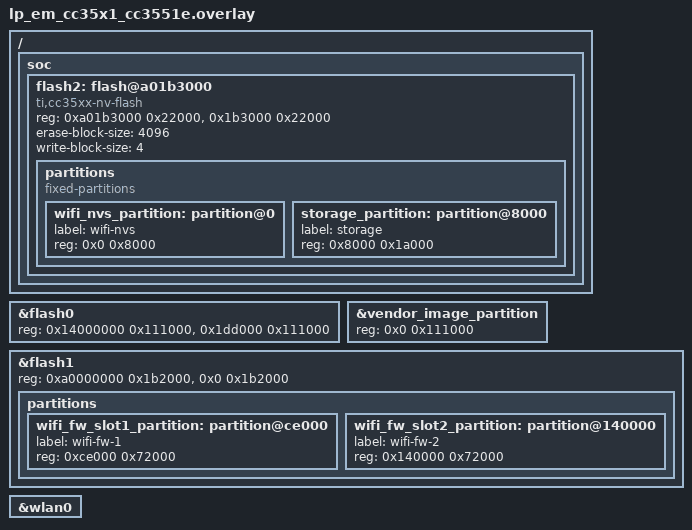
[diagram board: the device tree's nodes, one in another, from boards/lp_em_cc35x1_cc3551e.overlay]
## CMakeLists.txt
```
cmake_minimum_required(VERSION 3.20.0)

if(EXISTS "${CMAKE_CURRENT_SOURCE_DIR}/credentials.conf")
    list(APPEND EXTRA_CONF_FILE "${CMAKE_CURRENT_SOURCE_DIR}/credentials.conf")
endif()

find_package(Zephyr REQUIRED HINTS $ENV{ZEPHYR_BASE})
project(ota_psa)

if(NOT CONFIG_BOARD_LP_EM_CC35X1_CC3551E OR
    NOT CONFIG_CC35XXE_FLASH_PROFILE_IS25WJ032F OR
    NOT CONFIG_CC35XXE_GENERATE_FLASH_MAP_CONFIG)
    message(FATAL_ERROR
        "This sample requires lp_em_cc35x1/cc3551e and the generated is25wj032f OTA map")
endif()

# The overlay fixes physical addresses. A profile name alone cannot validate a
# custom map or discovery configuration against those addresses.
if(NOT "${CONFIG_CC35XXE_MEMORY_CONFIG_JSON}" STREQUAL "" OR
    NOT "${CONFIG_CC35XXE_FLASH_DISCOVERY_CONFIG_EXT_MEM}" STREQUAL "" OR
    NOT "${CONFIG_CC35XXE_FLASH_DISCOVERY_CONFIG_OTFDE}" STREQUAL "" OR
    NOT "${CONFIG_CC35XXE_FLASH_DISCOVERY_CONFIG_XSPI}" STREQUAL "")
    message(FATAL_ERROR "Custom flash maps require a matching sample overlay")
endif()

add_subdirectory(../net-common ${CMAKE_CURRENT_BINARY_DIR}/net-common)
target_sources(app PRIVATE src/main.c)
```

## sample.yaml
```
sample:
  name: Spotflow OTA through TI PSA Firmware Update
  description: Native signed vendor-image updates on CC35X1 with application-controlled commitment.
common:
  tags: [spotflow, ota, wifi]
  platform_allow: [lp_em_cc35x1/cc3551e]
tests:
  sample.spotflow.ota_psa:
    build_only: true
    extra_args: EXTRA_CONF_FILE=credentials-sample.conf
    integration_platforms: [lp_em_cc35x1/cc3551e]
```

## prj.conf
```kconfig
# Enable Spotflow and OTA updates
CONFIG_SPOTFLOW=y
CONFIG_SPOTFLOW_OTA=y

# Let the SDK handle download, PSA installation, and the installation reboot.
CONFIG_SPOTFLOW_OTA_AUTO_HANDLE_MAIN_FIRMWARE=y
CONFIG_SPOTFLOW_OTA_MAIN_FIRMWARE_PSA_FWU=y

# Enable Spotflow reboot and heartbeat metrics, disable others
CONFIG_SPOTFLOW_METRICS=y
CONFIG_SPOTFLOW_METRICS_HEARTBEAT=y
CONFIG_SPOTFLOW_METRICS_SYSTEM=y
CONFIG_SPOTFLOW_METRICS_SYSTEM_HEAP=n
CONFIG_SPOTFLOW_METRICS_SYSTEM_NETWORK=n
CONFIG_SPOTFLOW_METRICS_SYSTEM_CPU=n
CONFIG_SPOTFLOW_METRICS_SYSTEM_CONNECTION=n
CONFIG_SPOTFLOW_METRICS_SYSTEM_RESET_CAUSE=y
CONFIG_SPOTFLOW_METRICS_SYSTEM_STACK=n

# Enable logging
CONFIG_LOG=y

# Show function names in the logs
CONFIG_LOG_FUNC_NAME_PREFIX_INF=y
CONFIG_LOG_FUNC_NAME_PREFIX_WRN=y
CONFIG_LOG_FUNC_NAME_PREFIX_ERR=y

# Log details of OTA updates for debugging
CONFIG_SPOTFLOW_OTA_LOG_LEVEL=4

# Satisfy networking dependencies of Spotflow
CONFIG_NETWORKING=y
CONFIG_NET_MGMT=y
CONFIG_NET_MGMT_EVENT=y
CONFIG_NET_MGMT_EVENT_INFO=y
CONFIG_NET_CONFIG_AUTO_INIT=n
CONFIG_NET_CONNECTION_MANAGER=y
CONFIG_NET_DHCPV4=y
CONFIG_NET_IPV4=y
CONFIG_NET_IPV6=n
CONFIG_NET_TCP=y
CONFIG_NET_UDP=y

# Enable a persistent settings backend so OTA worker results can be saved and reported.
CONFIG_SETTINGS=y
CONFIG_NVS=y
CONFIG_SETTINGS_NVS=y

# Increase main stack size for the sample
CONFIG_MAIN_STACK_SIZE=4096

# Ensures that connection is established even on boards without hardware random number generator.
# We recommend removing this option for production use.
CONFIG_MBEDTLS_PSA_CRYPTO_EXTERNAL_RNG=y

# TI native image packaging, with two vendor slots. Increment for each update.
CONFIG_CC35XXE_FWU=y
CONFIG_CC35XXE_GENERATE_FLASH_MAP_CONFIG=y
CONFIG_CC35XXE_FLASH_PROFILE_IS25WJ032F=y
CONFIG_CC35XXE_VENDOR_IMAGE_VERSION="0.0.1.0"
```

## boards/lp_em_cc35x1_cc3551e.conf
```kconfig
CONFIG_NET_L2_ETHERNET=y
CONFIG_CRYPTO=y
CONFIG_CRYPTO_TI_CC35XX=y

# TI delivers RX bursts from a cooperative transport thread. Process them
# inline so the separate Zephyr RX thread cannot be starved behind that thread.
CONFIG_NET_TC_RX_COUNT=0

# The driver receives standard Ethernet frames, including a 1500-byte payload.
CONFIG_WIFI_TI_CC35XX_MTU=1500

# Legacy PSA RNG initialization requests CC35x entropy before the system workqueue starts,
# but the CC35x entropy driver needs that workqueue to refill its pool.
CONFIG_MBEDTLS_PSA_CRYPTO_EXTERNAL_RNG=y

# The TI downstream's Mbed TLS defaults take precedence over Spotflow's
# configdefault values. OTA needs a full TLS record and enough heap for the
# artifact HTTPS connection while the MQTT/TLS session remains connected.
CONFIG_MBEDTLS_SSL_MAX_CONTENT_LEN=16384
CONFIG_MBEDTLS_HEAP_SIZE=98304

# Provide headroom for packets retained by TCP and socket processing.
CONFIG_NET_PKT_RX_COUNT=32
CONFIG_NET_BUF_RX_COUNT=64

# Based on TI's CC35x1 Wi-Fi shell reference configuration:
# zephyr/samples/net/wifi/shell/boards/lp_em_cc35x1_cc3551e.conf
CONFIG_HEAP_MEM_POOL_SIZE=81920
CONFIG_MAIN_STACK_SIZE=61440
CONFIG_NET_TX_STACK_SIZE=2048
CONFIG_NET_RX_STACK_SIZE=2048
CONFIG_DYNAMIC_THREAD_POOL_SIZE=3
CONFIG_DYNAMIC_THREAD_STACK_SIZE=8192
```

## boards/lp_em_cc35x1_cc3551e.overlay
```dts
/* is25wj032f/ota: fixed factory layout; firmware OTA cannot migrate it.
 * PSA owns vendor-slot writes and logical mapping across slot changes.
 */
/* TI maps either physical vendor slot into this execution window when running. */
&flash0 {
	reg = <0x14000000 0x111000>, <0x1dd000 0x111000>;
};
&vendor_image_partition {
	reg = <0x0 0x111000>;
};

/* The Wi-Fi driver reads connectivity firmware from the selected wireless slot. */
&flash1 {
	reg = <0xa0000000 0x1b2000>, <0x0 0x1b2000>;
	partitions {
		/delete-node/ partition@68000;
		/delete-node/ partition@da000;
		wifi_fw_slot1_partition: partition@ce000 {
			label = "wifi-fw-1";
			reg = <0xce000 0x72000>;
		};
		wifi_fw_slot2_partition: partition@140000 {
			label = "wifi-fw-2";
			reg = <0x140000 0x72000>;
		};
	};
};

/* Starts after the protected-storage header and ends before ITS keys. */
/delete-node/ &flash2;
/ {
	soc {
		flash2: flash@a01b3000 {
			compatible = "ti,cc35xx-nv-flash";
			reg = <0xa01b3000 0x22000>, <0x1b3000 0x22000>;
			erase-block-size = <4096>;
			write-block-size = <4>;
			status = "okay";
			partitions {
				compatible = "fixed-partitions";
				#address-cells = <1>;
				#size-cells = <1>;
				wifi_nvs_partition: partition@0 {
					label = "wifi-nvs";
					reg = <0x0 0x8000>;
				};
				storage_partition: partition@8000 {
					label = "storage";
					reg = <0x8000 0x1a000>;
				};
			};
		};
	};
};

&wlan0 {
	status = "okay";
};
```

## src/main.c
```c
#include "net.h"

#include <spotflow/ota.h>
#include <psa_fwu.h>

#include <zephyr/kernel.h>
#include <zephyr/logging/log.h>

LOG_MODULE_REGISTER(ota_sample, LOG_LEVEL_INF);

static const char* ota_phase_name(enum spotflow_ota_phase phase);
static void confirm_unconfirmed_main_firmware(void);

void spotflow_on_main_firmware_update_progressed(
	const struct spotflow_ota_main_firmware_state* state)
{
	if (state == NULL) {
		return;
	}

	LOG_INF("Main firmware progress: phase=%s paused=%d result=%d",
		ota_phase_name(state->phase), state->is_paused, state->result);
}

enum spotflow_ota_result
spotflow_on_handle_firmware_update(const struct spotflow_firmware_info* info)
{
	if (info == NULL) {
		LOG_ERR("Non-main firmware callback received NULL info");
		return SPOTFLOW_OTA_RESULT_FAILED;
	}

	LOG_INF("Non-main firmware update requested: slug='%s' version=%s", info->slug,
		info->version);

	if (spotflow_is_update_canceled()) {
		LOG_INF("Non-main firmware update canceled before handling");
		return SPOTFLOW_OTA_RESULT_CANCELED;
	}

	/*
	 * Implement delegated firmware updates here. Use info->download_request with
	 * spotflow_download_artifact() to stream the artifact, then return a terminal
	 * spotflow_ota_result. This sample does not handle non-main artifacts.
	 */
	LOG_WRN("Non-main firmware updates are not implemented in this sample");
	return SPOTFLOW_OTA_RESULT_FAILED;
}

void spotflow_on_update_canceled(void)
{
	LOG_INF("OTA update canceled by the cloud");
}

int main(void)
{
	LOG_INF("Starting Spotflow PSA OTA sample");
	LOG_INF("TI vendor image version: %s", CONFIG_CC35XXE_VENDOR_IMAGE_VERSION);

	confirm_unconfirmed_main_firmware();

	/* Wait for the network device to initialize. */
	k_sleep(K_SECONDS(1));

	spotflow_sample_net_init();

	LOG_INF("Ready to receive OTA updates");

	return 0;
}

static const char* ota_phase_name(enum spotflow_ota_phase phase)
{
	switch (phase) {
	case SPOTFLOW_OTA_PHASE_NOT_RUNNING:
		return "NOT_RUNNING";
	case SPOTFLOW_OTA_PHASE_PENDING_DOWNLOAD:
		return "PENDING_DOWNLOAD";
	case SPOTFLOW_OTA_PHASE_DOWNLOADING:
		return "DOWNLOADING";
	case SPOTFLOW_OTA_PHASE_PENDING_UPGRADE:
		return "PENDING_UPGRADE";
	case SPOTFLOW_OTA_PHASE_PENDING_REBOOT:
		return "PENDING_REBOOT";
	case SPOTFLOW_OTA_PHASE_UNCONFIRMED:
		return "UNCONFIRMED";
	default:
		return "UNKNOWN";
	}
}

static void confirm_unconfirmed_main_firmware(void)
{
	struct spotflow_ota_main_firmware_state fw_state;
	int ret = spotflow_get_main_firmware_update_state(&fw_state);

	if (ret < 0) {
		LOG_ERR("Failed to query main firmware state: %d", ret);
		return;
	}

	if (fw_state.phase != SPOTFLOW_OTA_PHASE_UNCONFIRMED) {
		LOG_INF("Main firmware state: phase=%s result=%d", ota_phase_name(fw_state.phase),
			fw_state.result);
		return;
	}

	LOG_INF("Unconfirmed main firmware detected (phase=%s), confirming via Spotflow OTA",
		ota_phase_name(fw_state.phase));

	ret = spotflow_confirm_main_firmware_image(&fw_state);
	if (ret < 0) {
		LOG_ERR("Failed to confirm main firmware image: %d (phase=%s result=%d)", ret,
			ota_phase_name(fw_state.phase), fw_state.result);
		return;
	}

	/* Demo only: replace immediate acceptance with application health checks.
	 * TI acceptance becomes durable only after this PSA reboot.
	 * Spotflow confirmation itself never requests a reboot.
	 */
	if (fw_state.phase == SPOTFLOW_OTA_PHASE_UNCONFIRMED) {
		LOG_INF("Acceptance requested; rebooting through TI PSA FWU to confirm the image");
		psa_status_t status = psa_fwu_request_reboot();

		if (status != PSA_SUCCESS) {
			LOG_ERR("Confirmation reboot request failed: %d; update remains pending",
				status);
		}
	} else {
		LOG_INF("Main firmware confirmed (phase=%s result=%d)",
			ota_phase_name(fw_state.phase), fw_state.result);
	}
}
```
